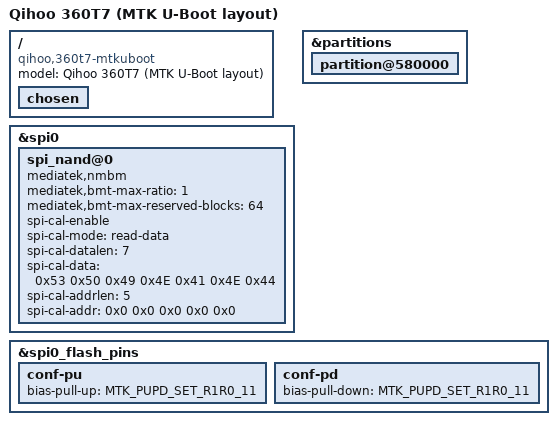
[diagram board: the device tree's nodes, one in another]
// SPDX-License-Identifier: GPL-2.0-or-later OR MIT

/*
 * Qihoo 360T7 for hanwckf's U-Boot (bl-mt798x, NMBM, 108M UBI layout).
 *
 * Layout (identical to hanwckf's mt7981-360-t7-108M):
 *   bl2 / u-boot-env / Factory / fip / ubi(0x580000, 108M) / config / factory / log
 * The kernel (FIT) lives in the UBI volume "kernel", rootfs in "rootfs";
 * flash *-squashfs-factory.bin from the U-Boot failsafe web page.
 */

/dts-v1/;
#include "../dts/mt7981b-qihoo-360t7.dts"

/ {
	model = "Qihoo 360T7 (MTK U-Boot layout)";
	compatible = "qihoo,360t7-mtkuboot", "mediatek,mt7981";

	chosen {
		/delete-property/ bootargs-append;
		/delete-property/ rootdisk;
	};
};

&spi0 {
	spi_nand@0 {
		mediatek,nmbm;
		mediatek,bmt-max-ratio = <1>;
		mediatek,bmt-max-reserved-blocks = <64>;

		spi-cal-enable;
		spi-cal-mode = "read-data";
		spi-cal-datalen = <7>;
		spi-cal-data = /bits/ 8 <0x53 0x50 0x49 0x4E 0x41 0x4E 0x44>;
		spi-cal-addrlen = <5>;
		spi-cal-addr = /bits/ 32 <0x0 0x0 0x0 0x0 0x0>;
	};
};

&partitions {
	partition@580000 {
		/* ubi */
		/delete-node/ volumes;
	};
};

&spi0_flash_pins {
	conf-pu {
		/delete-property/ bias-disable;
		bias-pull-up = <MTK_PUPD_SET_R1R0_11>;
	};

	conf-pd {
		/delete-property/ bias-disable;
		bias-pull-down = <MTK_PUPD_SET_R1R0_11>;
	};
};
